# STM32G553 register map
File version: 2.0.0
CPU: CM33 r0p4, little endian, MPU, FPU, 4 interrupt priority bits
Registers are 32-bit, read-write, reset 0x0 unless marked. A register's access mark holds for its fields unless they carry their own. Offsets are from the block's base; [hi:lo] are bit positions; {n}, {i} and the like mark numbered series.

## DLYB — DLYB address block description
Base 0x4600F000
Same registers: DLYB_S 0x5600F000
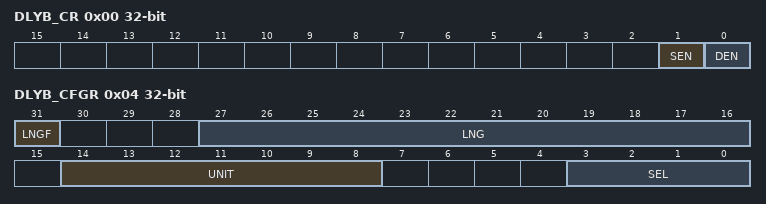
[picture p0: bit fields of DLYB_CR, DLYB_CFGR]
0x00 DLYB_CR — DLYB control register
  [1] SEN — Sampler length enable bit
    0=Sampler length and register access to UNIT[6:0] and SEL[3:0] disabled, output clock enabled; 1=Sampler length and register access to UNIT[6:0] and SEL[3:0] enabled, output clock disabled
  [0] DEN — Delay block enable bit
    0=DLYB disabled; 1=DLYB enabled
0x04 DLYB_CFGR — DLYB configuration register
  [31] LNGF ro — Length valid flag
    0=Length value in LNG is not valid; 1=Length value in LNG is valid
  [27:16] LNG ro — Delay line length value
  [14:8] UNIT — Delay of a unit delay cell.
  [3:0] SEL — Phase for the output clock.

## GTZC1_MPCBB3 — GTZC1_MPCBB3 register block
Base 0x40033400
Same registers: GTZC1_MPCBB3_S 0x50033400
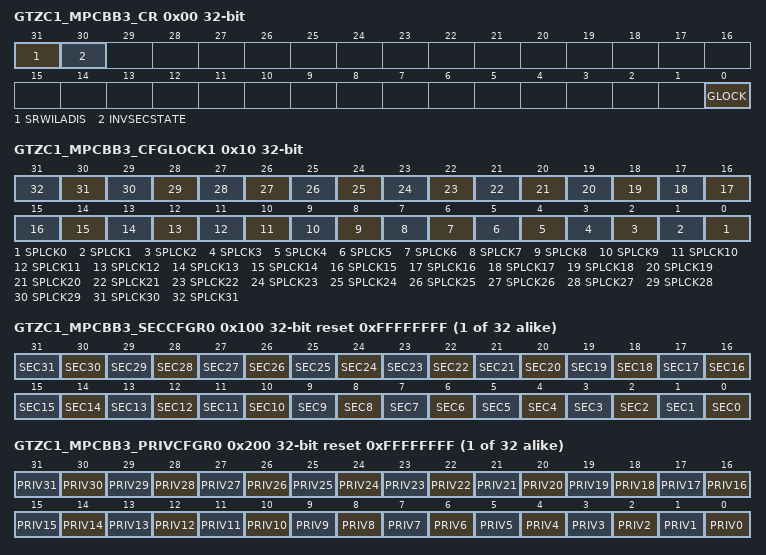
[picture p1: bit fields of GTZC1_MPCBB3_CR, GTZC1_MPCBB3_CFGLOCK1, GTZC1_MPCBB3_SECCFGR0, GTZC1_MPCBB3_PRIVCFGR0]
0x00 GTZC1_MPCBB3_CR — PLAYGTZC1 SRAM3 MPCBB control register
  [31] SRWILADIS — secure read/write illegal access disable
    0=enabled, secure read/write access not allowed on nonsecure SRAM block; 1=disabled, secure read/write access allowed on nonsecure SRAM block
  [30] INVSECSTATE — SRAMx clocks security state
    0=SRAMs clocks are secure if a secure area exists in the MPCBB; 1=SRAMs clocks are nonsecure even if a secure area exists in the MPCBB, and secure even if no secure block is set in the MPCBB
  [0] GLOCK — lock the control register of the MPCBB until next reset
    0=control register not locked; 1=control register locked
0x10 GTZC1_MPCBB3_CFGLOCK1 — GTZC1 SRAM3 MPCBB configuration lock register 1
  [all] fields
    0=GTZC1_MPCBBz_SECCFGRy and GTZC1_MPCBBz_PRIVCFGRy can be written; 1=Writes to GTZC1_MPCBBz_SECCFGRy and GTZC1_MPCBBz_PRIVCFGRy are ignored
  [n] SPLCK{n} (n=0..31) — Security/privilege configuration lock for super-block
{0x100+4i} GTZC1_MPCBB3_SECCFGR{i} reset 0xFFFFFFFF (i=0..31) — GTZC1 SRAM3 MPCBB security configuration for super-block {i} register
  [all] fields
    0=nonsecure access only to block y, belonging to super-block x; 1=Secure access only to block y, belonging to super-block x
  [n] SEC{n} (n=0..31) — Security configuration for block y
{0x200+4i} GTZC1_MPCBB3_PRIVCFGR{i} reset 0xFFFFFFFF (i=0..31) — GTZC1 SRAM3 MPCBB privileged configuration for super-block {i} register
  [all] fields
    0=Privileged and unprivileged access to block y, belonging to super-block x; 1=Only privileged access to block y, belonging to super-block x
  [n] PRIV{n} (n=0..31) — Privileged configuration for block y, belonging to super-block x (y = 31 to 0).

## GTZC1_MPCBB2 — GTZC1_MPCBB2 register block
Base 0x40033000
Same registers: GTZC1_MPCBB2_S 0x50033000
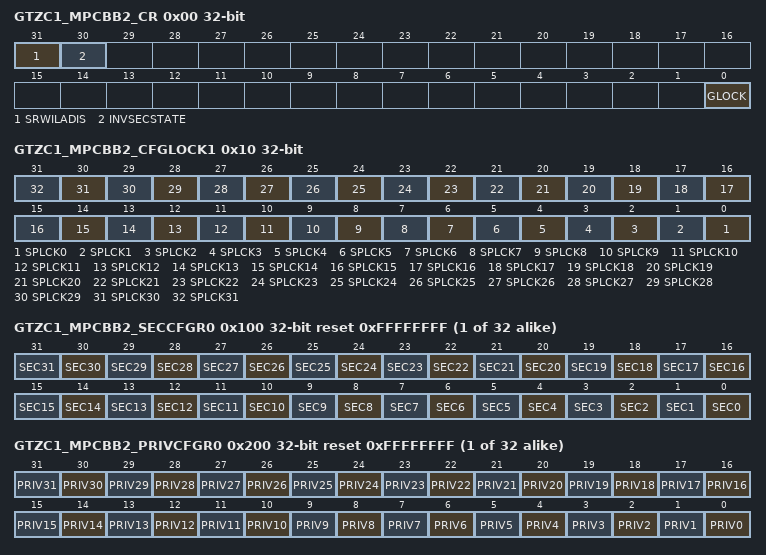
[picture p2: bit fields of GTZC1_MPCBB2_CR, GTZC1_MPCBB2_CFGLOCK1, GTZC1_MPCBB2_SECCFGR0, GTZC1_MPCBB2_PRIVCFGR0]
0x00 GTZC1_MPCBB2_CR — PLAYGTZC1 SRAM2 MPCBB control register
  [31] SRWILADIS — secure read/write illegal access disable
    0=enabled, secure read/write access not allowed on nonsecure SRAM block; 1=disabled, secure read/write access allowed on nonsecure SRAM block
  [30] INVSECSTATE — SRAMx clocks security state
    0=SRAMs clocks are secure if a secure area exists in the MPCBB; 1=SRAMs clocks are nonsecure even if a secure area exists in the MPCBB, and secure even if no secure block is set in the MPCBB
  [0] GLOCK — lock the control register of the MPCBB until next reset
    0=control register not locked; 1=control register locked
0x10 GTZC1_MPCBB2_CFGLOCK1 — GTZC1 SRAM2 MPCBB configuration lock register 1
  [all] fields
    0=GTZC1_MPCBBz_SECCFGRy and GTZC1_MPCBBz_PRIVCFGRy can be written; 1=Writes to GTZC1_MPCBBz_SECCFGRy and GTZC1_MPCBBz_PRIVCFGRy are ignored
  [n] SPLCK{n} (n=0..31) — Security/privilege configuration lock for super-block
{0x100+4i} GTZC1_MPCBB2_SECCFGR{i} reset 0xFFFFFFFF (i=0..31) — GTZC1 SRAM2 MPCBB security configuration for super-block {i} register
  [all] fields
    0=nonsecure access only to block y, belonging to super-block x; 1=Secure access only to block y, belonging to super-block x
  [n] SEC{n} (n=0..31) — Security configuration for block y
{0x200+4i} GTZC1_MPCBB2_PRIVCFGR{i} reset 0xFFFFFFFF (i=0..31) — GTZC1 SRAM2 MPCBB privileged configuration for super-block {i} register
  [all] fields
    0=Privileged and unprivileged access to block y, belonging to super-block x; 1=Only privileged access to block y, belonging to super-block x
  [n] PRIV{n} (n=0..31) — Privileged configuration for block y, belonging to super-block x (y = 31 to 0).
